# ADuCM4050 register map
Vendor: Analog Devices; Series: ADuCM4050; File version: 1p0
CPU: CM4 r0p1, little endian, MPU, FPU, 3 interrupt priority bits
Registers are 32-bit, read-write, reset 0x0 unless marked. A register's access mark holds for its fields unless they carry their own. Offsets are from the block's base; [hi:lo] are bit positions; {n}, {i} and the like mark numbered series.

## XINT0 — External interrupt configuration
Base 0x4004C080
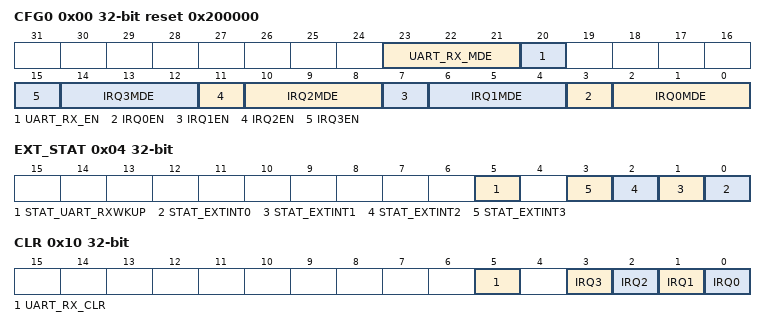
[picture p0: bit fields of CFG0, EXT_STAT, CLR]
0x00 CFG0 reset 0x200000 — External Interrupt Configuration
  [23:21] UART_RX_MDE — External Interrupt Using UART_RX Wakeup Mode Registers
  [20] UART_RX_EN — External Interrupt Using UART_RX Enable Bit
  [4n+3] IRQ{n}EN (n=0..3) — External Interrupt {n} Enable
  [4n+2:4n] IRQ{n}MDE (n=0..3) — External Interrupt {n} Mode Registers
0x04 EXT_STAT — External Wakeup Interrupt Status
  [5] STAT_UART_RXWKUP ro — Interrupt Status Bit for UART RX WAKEUP Interrupt
  [n] STAT_EXTINT{n} ro (n=0..3) — Interrupt Status Bit for External Interrupt {n}
0x10 CLR — External Interrupt Clear
  [5] UART_RX_CLR range 0x00000000..0x00000001 — External Interrupt Clear for UART_RX WAKEUP Interrupt
  [n] IRQ{n} range 0x00000000..0x00000001 (n=0..3) — External Interrupt {n}
0x14 NMICLR — Non-maskable Interrupt Clear
  [0] CLR range 0x00000000..0x00000001 — NMI Clear

## CLKG0_OSC — Clocking
Base 0x4004C100
0x0C KEY — Key Protection for OSCCTRL
  [15:0] VALUE wo range 0x00000000..0x0000FFFF — Oscillator key
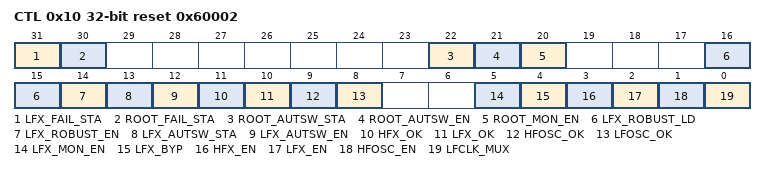
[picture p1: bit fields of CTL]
0x10 CTL reset 0x60002 — Oscillator Control
  [31] LFX_FAIL_STA range 0x00000000..0x00000001 — LF XTAL (crystal clock) Not Stable
  [30] ROOT_FAIL_STA range 0x00000000..0x00000001 — Root clock (crystal clock) Not Stable
  [22] ROOT_AUTSW_STA — Status of automatic switching of the Root clock to HFOSC upon detection of Root clock failure
  [21] ROOT_AUTSW_EN — Enables automatic Switching of the Root clock to HFOSC on Root clock Failure
  [20] ROOT_MON_EN — ROOT clock monitor and Clock FAIL interrupt enable
  [16:15] LFX_ROBUST_LD — LFXTAL Robust Mode Load select
  [14] LFX_ROBUST_EN — LFXTAL Mode select
  [13] LFX_AUTSW_STA — Status of automatic switching of the LF Mux to LFOSC upon detection of LFXTAL failure
  [12] LFX_AUTSW_EN — Enables automatic Switching of the LF Mux to LFOSC on LFXTAL Failure
  [11] HFX_OK ro — Status of HFXTAL oscillator
  [10] LFX_OK ro — Status of LFXTAL oscillator
  [9] HFOSC_OK ro — Status of HFOSC oscillator
  [8] LFOSC_OK ro — Status of LFOSC oscillator
  [5] LFX_MON_EN — LFXTAL clock monitor and Clock FAIL interrupt enable
  [4] LFX_BYP — Low frequency crystal oscillator Bypass
  [3] HFX_EN — High frequency crystal oscillator enable
  [2] LFX_EN — Low frequency crystal oscillator enable
  [1] HFOSC_EN — High frequency internal oscillator enable
  [0] LFCLK_MUX — 32 kHz clock select mux

## PMG0_TST — Power Management
Base 0x4004C200
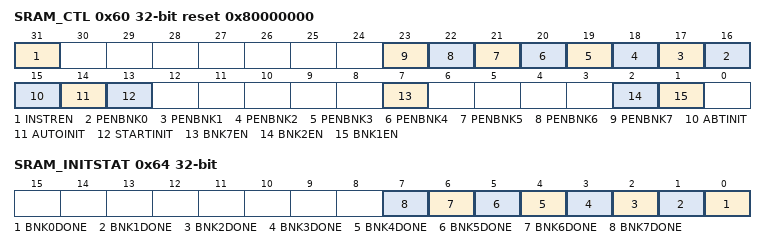
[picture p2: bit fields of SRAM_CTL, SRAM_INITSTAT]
0x60 SRAM_CTL reset 0x80000000 — Control for SRAM Parity and Instruction SRAM
  [31] INSTREN range 0x00000000..0x00000001 — Enables 32kB Instruction SRAM
  [n+16] PENBNK{n} range 0x00000000..0x00000001 (n=0..7) — Enable Parity Check
  [15] ABTINIT range 0x00000000..0x00000001 — Abort Current Initialization. Self-cleared
  [14] AUTOINIT range 0x00000000..0x00000001 — Automatic Initialization on Wake up from Hibernate Mode
  [13] STARTINIT range 0x00000000..0x00000001 — Start Manual Initialization
  [7] BNK7EN range 0x00000000..0x00000001 — Enable Initialization
  [2] BNK2EN range 0x00000000..0x00000001 — Enable Initialization
  [1] BNK1EN range 0x00000000..0x00000001 — Enable Initialization
0x64 SRAM_INITSTAT — Initialization Status Register
  [n] BNK{n}DONE ro (n=0..7) — Bank {n} Initialization Status
    0=NO_BANK{n}_INIT (Bank {n} not initialized); 1=BANK{n}_INIT (Bank {n} initialized)
0x68 CLR_LATCH_GPIOS 16-bit — Clear GPIO After Shutdown Mode
  [15:0] VALUE wo range 0x00000000..0x0000FFFF — Clear the Latches for GPIOs
0x6C SCRPAD_IMG — Scratch Pad Image
  [31:0] DATA range 0x00000000..0xFFFFFFFF — Scratch Image
0x70 SCRPAD_3V_RD — Scratch Pad Saved in Battery Domain
  [31:0] DATA ro — Reading the Scratch Pad Stored in Shutdown Mode
0x74 FAST_SHT_WAKEUP — Fast Shutdown Wake-up Enable
  [0] FAST_SHT_WAKEUP — Enables Fast Shutdown Wake-up
    0=FASTWAKE_DIS (Fast shutdown wakeup is disabled); 1=FASTWAKE_EN (Fast shutdown wakeup is enabled)
